# A64 register map
Vendor: Allwinner; Series: A64; File version: 0.1
CPU: CA53 0, little endian, MPU, no FPU, 0 interrupt priority bits
Registers are 32-bit, read-write, reset 0x0 unless marked. A register's access mark holds for its fields unless they carry their own. Offsets are from the block's base; [hi:lo] are bit positions; lines under a group give offsets from that group; {n}, {i} and the like mark numbered series.

## DMA
Base 0x01C02000
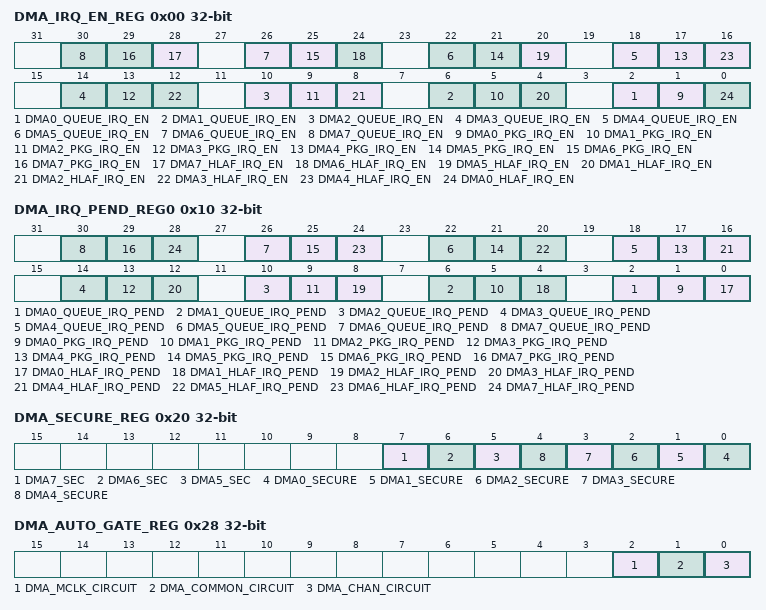
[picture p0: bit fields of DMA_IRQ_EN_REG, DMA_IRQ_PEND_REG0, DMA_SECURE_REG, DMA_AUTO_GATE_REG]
0x00 DMA_IRQ_EN_REG — DMA IRQ Enable Register
  [all] fields
    0=Disable, 1: Enable
  [4n+2] DMA{n}_QUEUE_IRQ_EN (n=0..7) — DMA {n} Queue End Transfer Interrupt Enable. 0: Disable, 1: Enable.
  [4n+1] DMA{n}_PKG_IRQ_EN (n=0..7) — DMA {n} Package End Transfer Interrupt Enable. 0: Disable, 1: Enable.
  [28] DMA7_HLAF_IRQ_EN — DMA 7 Half Package Transfer Interrupt Enable. 0: Disable, 1: Enable.
  [24] DMA6_HLAF_IRQ_EN — DMA 6 Half Package Transfer Interrupt Enable. 0: Disable, 1: Enable.
  [20] DMA5_HLAF_IRQ_EN — DMA 5 Half package Transfer Interrupt Enable. 0: Disable, 1: Enable.
  [4n] DMA{n}_HLAF_IRQ_EN (n=1..4) — DMA {n} Half Package Transfer Interrupt Enable. 0: Disable, 1: Enable.
  [0] DMA0_HLAF_IRQ_EN — DMA 0 Half Package Transfer Interrupt Enable. 0: Disable, 1: Enable
0x10 DMA_IRQ_PEND_REG0
  [all] fields
    0=No effect, 1: Pending
  [4n+2] DMA{n}_QUEUE_IRQ_PEND (n=0..7) — DMA {n} Queue End Transfer Interrupt Pending. Set 1 to the bit will clear it. 0: No effect, 1: Pending.
  [4n+1] DMA{n}_PKG_IRQ_PEND (n=0..7) — DMA {n} Package End Transfer Interrupt Pending. Set 1 to the bit will clear it. 0: No effect, 1: Pending.
  [4n] DMA{n}_HLAF_IRQ_PEND (n=0..7) — DMA {n} Half Package Transfer Interrupt Pending. Set 1 to the bit will clear it. 0: No effect, 1: Pending.
0x20 DMA_SECURE_REG
  [all] fields
    0=Secure; 1=non_secure
  [7] DMA7_SEC — DMA channel 7 security. 0: Secure, 1: Non-secure.
  [6] DMA6_SEC — DMA channel 6 security. 0: Secure, 1: Non-secure.
  [5] DMA5_SEC — DMA channel 5 security. 0: Secure, 1: Non-secure.
  [n] DMA{n}_SECURE (n=0..4) — Indicating DMA {n} security. 0: Secure, 1: Non-secure.
0x28 DMA_AUTO_GATE_REG — DMA Auto Gating Register
  [all] fields
    0=Auto_gating_enable; 1=Auto gating disable
  [2] DMA_MCLK_CIRCUIT — DMA MCLK interface circuit auto gating bit. 0: Auto gating enable 1: Auto gating disable.
  [1] DMA_COMMON_CIRCUIT — DMA common circuit auto gating bit. 0: Auto gating enable 1: Auto gating disable.
  [0] DMA_CHAN_CIRCUIT — DMA channel circuit auto gating bit. 0: Auto gating enable 1: Auto gating disable.
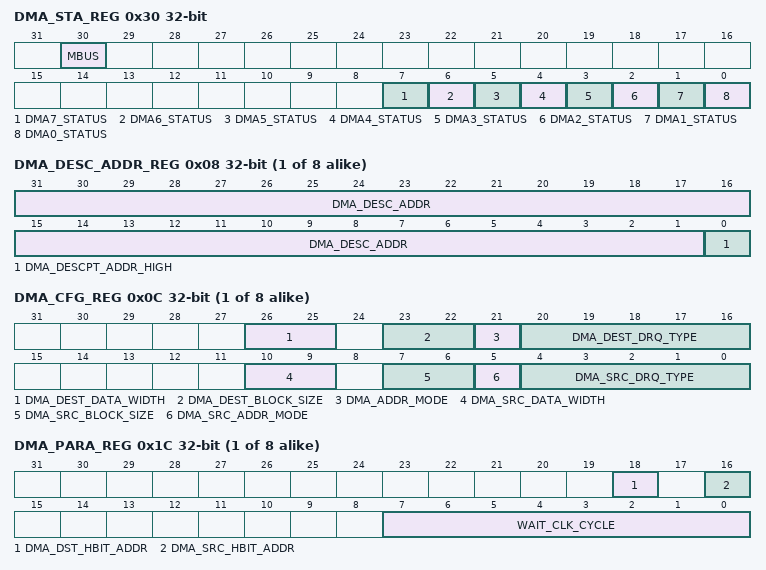
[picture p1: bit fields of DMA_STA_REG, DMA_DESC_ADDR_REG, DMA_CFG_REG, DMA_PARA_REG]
0x30 DMA_STA_REG — DMA Status Register
  [30] MBUS ro — FIFO Status 0:Empty 1:Not Empty
  [7] DMA7_STATUS ro — DMA Channel 7 Status. 0: Idle 1: Busy
    0=Idle; 1=Busy
  [6] DMA6_STATUS ro — DMA Channel 6 Status. 0: Idle 1: Busy
    0=Idle; 1=Busy
  [5] DMA5_STATUS ro — DMA Channel 5 Status. 0: Idle 1: Busy
    0=Idle; 1=Busy
  [4] DMA4_STATUS ro — DMA Channel 4 Status. 0: Idle 1: Busy.
    0=Idle; 1=Busy
  [3] DMA3_STATUS ro — DMA Channel 3 Status. 0: Idle 1: Busy.
    0=Idle; 1=Busy
  [2] DMA2_STATUS ro — DMA Channel 2 Status. 0: Idle, 1: Busy.
    0=Idle; 1=Busy
  [1] DMA1_STATUS ro — DMA Channel 1 Status. 0: Idle, 1: Busy.
    0=Idle; 1=Busy
  [0] DMA0_STATUS ro — DMA Channel 0 Status. 0: Idle, 1: Busy.
    0=Idle; 1=Busy
{0x100+0x40*i} _N[{i}] (i=0..7) group
  0x00 DMA_EN_REG — DMA Channel Enable Register (N=0~7)
    [0] DMA_EN — DMA Channel Enable 0: Disable 1: Enable.
      0=Disable; 1=Enable
  0x04 DMA_PAU_REG — DMA Channel Pause Register (N=0~7)
    [0] DMA_PAUSE — Pausing DMA Channel Transfer Data. 0: Resume Transferring, 1: Pause Transferring.
      0=Resume Transferring,; 1=Pause Transferring
  0x08 DMA_DESC_ADDR_REG — DMA Channel Start Address Register (N=0~7)
    [31:1] DMA_DESC_ADDR — DMA Channel Descriptor Address. The Descriptor Address must be half-word aligned before DMA enable.
    [0] DMA_DESCPT_ADDR_HIGH — This bit would be used to storing [32] bits of the descriptor address, if it is necessary. Otherwise, it should be 0.
  0x0C DMA_CFG_REG — DMA Channel Configuration Register (N=0~7)
    [26:25] DMA_DEST_DATA_WIDTH ro — DMA Destination Data Width. 00: 8-bit 01: 16-bit 10: 32-bit 11: 64-bit
      0=_8_bit; 1=_16_bit; 2=_32_bit; 3=_64_bit
    [23:22] DMA_DEST_BLOCK_SIZE ro — DMA Destination Block Size. 00: 1 01: 4 10: 8 11: 16
      0=_1; 1=_4; 2=_8; 3=_16
    [21] DMA_ADDR_MODE ro — DMA Destination Address Mode 0: Linear Mode 1: IO Mode
      0=Linear Mode; 1=IO (IO Mode)
    [20:16] DMA_DEST_DRQ_TYPE ro — DMA Destination DRQ Type The details in DRQ Type and Port Corresponding Relation.
    [10:9] DMA_SRC_DATA_WIDTH ro — DMA Source Data Width. 00: 8-bit 01: 16-bit 10: 32-bit 11: 64-bit
      0=_8_bit; 1=_16_bit; 2=_32_bit; 3=_64_bit
    [7:6] DMA_SRC_BLOCK_SIZE ro — DMA Source Block Size. 00: 1 01: 4 10: 8 11: 16
      0=_1; 1=_4; 2=_8; 3=_16
    [5] DMA_SRC_ADDR_MODE ro — DMA Source Address Mode 0: Linear Mode 1: IO Mode
      0=Linear Mode; 1=IO (IO Mode)
    [4:0] DMA_SRC_DRQ_TYPE ro — DMA Source DRQ Type The details in DRQ Type and Port Corresponding Relation.
  0x10 DMA_CUR_SRC_REG — (N=0~7)
    [31:0] DMA_CUR_SRC ro — DMA Channel Current Source Address, read only.
  0x14 DMA_CUR_DEST_REG — DMA Channel Current Destination Register (N=0~7)
    [31:0] DMA_CUR_DEST ro — DMA Channel Current Destination Address, read only.
  0x18 DMA_BCNT_LEFT_REG — DMA Channel Byte Counter Left Register (N=0~7)
    [24:0] DMA_BCNT_LEFT ro — DMA Channel Byte Counter Left, read only.
  0x1C DMA_PARA_REG — DMA Channel Parameter Register (N=0~7)
    [18] DMA_DST_HBIT_ADDR ro
    [16] DMA_SRC_HBIT_ADDR ro
    [7:0] WAIT_CLK_CYCLE ro — Wait clock cycle.
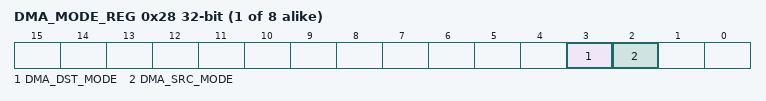
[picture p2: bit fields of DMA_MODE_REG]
  0x28 DMA_MODE_REG
    [3] DMA_DST_MODE — 0: Wait mode. 1: Handshake mode.
      0=Wait mode; 1=Handshake mode
    [2] DMA_SRC_MODE — 0: Wait mode. 1: Handshake mode.
      0=Wait mode; 1=Handshake mode
  0x2C DMA_FDESC_ADDR_REG — DMA Formar Descriptor Address Register (N=0~7)
    [31:0] DMA_FDESC_ADDR ro — This register is used to storing the former value of DMA Channel Descriptor Address Register .
  0x30 DMA_PKG_NUM_REG — DMA Package Number Register (N=0~7)
    [31:0] DMA_PKG_NUM ro — This register will record the number of packages which has been completed in one transmission.
